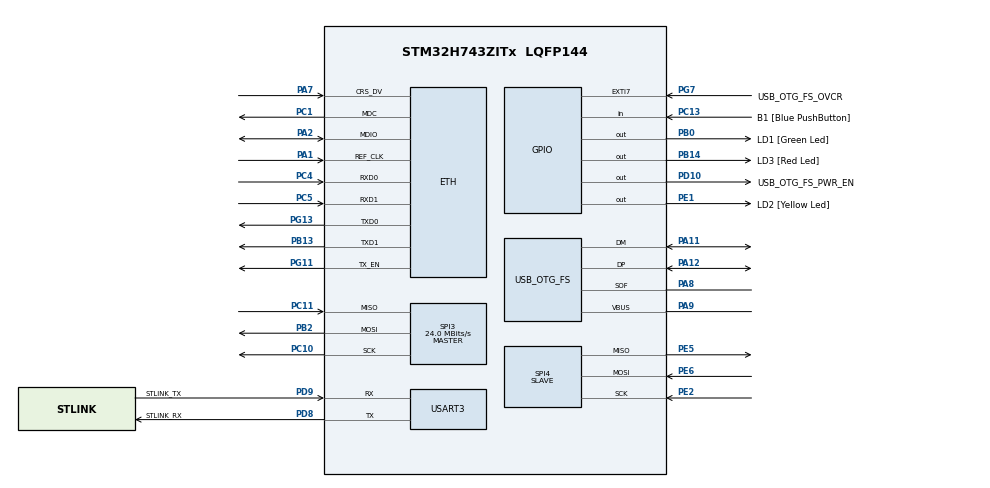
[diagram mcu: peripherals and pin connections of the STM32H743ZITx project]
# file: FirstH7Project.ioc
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Dma.Request0=SPI4_RX
Dma.SPI4_RX.0.Direction=DMA_PERIPH_TO_MEMORY
Dma.SPI4_RX.0.EventEnable=DISABLE
Dma.SPI4_RX.0.FIFOMode=DMA_FIFOMODE_DISABLE
Dma.SPI4_RX.0.Instance=DMA1_Stream0
Dma.SPI4_RX.0.MemDataAlignment=DMA_MDATAALIGN_HALFWORD
Dma.SPI4_RX.0.MemInc=DMA_MINC_ENABLE
Dma.SPI4_RX.0.Mode=DMA_NORMAL
Dma.SPI4_RX.0.PeriphDataAlignment=DMA_PDATAALIGN_HALFWORD
Dma.SPI4_RX.0.PeriphInc=DMA_PINC_DISABLE
Dma.SPI4_RX.0.Polarity=HAL_DMAMUX_REQ_GEN_RISING
Dma.SPI4_RX.0.Priority=DMA_PRIORITY_LOW
Dma.SPI4_RX.0.RequestNumber=1
Dma.SPI4_RX.0.SignalID=NONE
Dma.SPI4_RX.0.SyncEnable=DISABLE
Dma.SPI4_RX.0.SyncPolarity=HAL_DMAMUX_SYNC_NO_EVENT
Dma.SPI4_RX.0.SyncRequestNumber=1
Dma.SPI4_RX.0.SyncSignalID=NONE
ETH.MediaInterface=HAL_ETH_RMII_MODE
Mcu.Family=STM32H7
Mcu.Name=STM32H743ZITx
Mcu.Package=LQFP144
NVIC.DMA1_Stream0_IRQn=true\:0\:0\:false\:false\:true\:false\:true
NVIC.OTG_FS_IRQn=true\:0\:0\:false\:false\:true\:false\:true
NVIC.PriorityGroup=NVIC_PRIORITYGROUP_4
NVIC.SPI4_IRQn=true\:0\:0\:false\:false\:true\:false\:true
PA1.Mode=RMII
PA1.Signal=ETH_REF_CLK
PA11.Mode=Device_Only
PA11.Signal=USB_OTG_FS_DM
PA12.Mode=Device_Only
PA12.Signal=USB_OTG_FS_DP
PA2.Mode=RMII
PA2.Signal=ETH_MDIO
PA7.Mode=RMII
PA7.Signal=ETH_CRS_DV
PA8.Mode=Activate_SOF_FS
PA8.Signal=USB_OTG_FS_SOF
PA9.Mode=Activate_VBUS
PA9.Signal=USB_OTG_FS_VBUS
PB0.GPIO_Label=LD1 [Green Led]
PB0.Signal=GPIO_Output
PB13.Mode=RMII
PB13.Signal=ETH_TXD1
PB14.GPIO_Label=LD3 [Red Led]
PB14.Signal=GPIO_Output
PB2.Mode=Full_Duplex_Master
PB2.Signal=SPI3_MOSI
PC1.Mode=RMII
PC1.Signal=ETH_MDC
PC10.Mode=Full_Duplex_Master
PC10.Signal=SPI3_SCK
PC11.Mode=Full_Duplex_Master
PC11.Signal=SPI3_MISO
PC13.GPIO_Label=B1 [Blue PushButton]
PC13.Signal=GPIO_Input
PC14-OSC32_IN\ (OSC32_IN).Mode=LSE-External-Oscillator
PC14-OSC32_IN\ (OSC32_IN).Signal=RCC_OSC32_IN
PC15-OSC32_OUT\ (OSC32_OUT).Mode=LSE-External-Oscillator
PC15-OSC32_OUT\ (OSC32_OUT).Signal=RCC_OSC32_OUT
PC4.Mode=RMII
PC4.Signal=ETH_RXD0
PC5.Mode=RMII
PC5.Signal=ETH_RXD1
PD10.GPIO_Label=USB_OTG_FS_PWR_EN
PD10.Signal=GPIO_Output
PD8.GPIO_Label=STLINK_RX
PD8.Mode=Asynchronous
PD8.Signal=USART3_TX
PD9.GPIO_Label=STLINK_TX
PD9.Mode=Asynchronous
PD9.Signal=USART3_RX
PE1.GPIO_Label=LD2 [Yellow Led]
PE1.Signal=GPIO_Output
PE2.Mode=Full_Duplex_Slave
PE2.Signal=SPI4_SCK
PE5.Mode=Full_Duplex_Slave
PE5.Signal=SPI4_MISO
PE6.Mode=Full_Duplex_Slave
PE6.Signal=SPI4_MOSI
PG11.Mode=RMII
PG11.Signal=ETH_TX_EN
PG13.Mode=RMII
PG13.Signal=ETH_TXD0
PG7.GPIO_Label=USB_OTG_FS_OVCR
PG7.Signal=GPXTI7
PH0-OSC_IN\ (PH0).Mode=HSE-External-Clock-Source
PH0-OSC_IN\ (PH0).Signal=RCC_OSC_IN
PH1-OSC_OUT\ (PH1).Signal=RCC_OSC_OUT
ProjectManager.HeapSize=0x200
ProjectManager.StackSize=0x400
ProjectManager.TargetToolchain=Makefile
RCC.ADCFreq_Value=16125000
RCC.APB1Freq_Value=64000000
RCC.APB2Freq_Value=64000000
RCC.APB3Freq_Value=64000000
RCC.APB4Freq_Value=64000000
RCC.CortexFreq_Value=64000000
RCC.DIVM1=1
RCC.DIVN1=24
RCC.DIVQ1=4
RCC.HCLKFreq_Value=64000000
RCC.HSE_VALUE=8000000
RCC.PLLFRACN=0
RCC.SYSCLKFreq_VALUE=64000000
RCC.USBFreq_Value=48000000
SPI3.CalculateBaudRate=24.0 MBits/s
SPI3.Direction=SPI_DIRECTION_2LINES
SPI3.Mode=SPI_MODE_MASTER
SPI3.VirtualType=VM_MASTER
SPI4.Direction=SPI_DIRECTION_2LINES
SPI4.Mode=SPI_MODE_SLAVE
SPI4.VirtualType=VM_SLAVE
USART3.VirtualMode-Asynchronous=VM_ASYNC
USB_DEVICE.CLASS_NAME_FS=AUDIO
USB_DEVICE.VirtualMode-AUDIO_FS=Audio
USB_DEVICE.VirtualModeFS=Audio_FS
USB_OTG_FS.VirtualMode=Device_Only
VP_DMA2D_VS_DMA2D.Mode=DMA2D_Activate
VP_USB_DEVICE_VS_USB_DEVICE_AUDIO_FS.Mode=AUDIO_FS
board=NUCLEO-H743ZI2

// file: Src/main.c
/* USER CODE BEGIN Header */
/**
  ******************************************************************************
  * @file           : main.c
  * @brief          : Main program body
  ******************************************************************************
  * @attention
  *
  * <h2><center>&copy; Copyright (c) 2020 STMicroelectronics.
  * All rights reserved.</center></h2>
  *
  * This software component is licensed by ST under BSD 3-Clause license,
  * the "License"; You may not use this file except in compliance with the
  * License. You may obtain a copy of the License at:
  *                        opensource.org/licenses/BSD-3-Clause
  *
  ******************************************************************************
  */
/* USER CODE END Header */
#include "main.h"
#include "dma.h"
#include "dma2d.h"
#include "eth.h"
#include "spi.h"
#include "usart.h"
#include "usb_device.h"
#include "gpio.h"

void SystemClock_Config(void);

int main(void)
{

  /* MCU Configuration--------------------------------------------------------*/

  /* Reset of all peripherals, Initializes the Flash interface and the Systick. */
  HAL_Init();

  /* Configure the system clock */
  SystemClock_Config();

  /* Initialize all configured peripherals */
  MX_GPIO_Init();
  MX_DMA_Init();
  MX_ETH_Init();
  MX_USART3_UART_Init();
  MX_SPI3_Init();
  MX_SPI4_Init();
  MX_USB_DEVICE_Init();
  MX_DMA2D_Init();

  /* Infinite loop */
  /* USER CODE BEGIN WHILE */
    while (1)
    {
        if (HAL_GPIO_ReadPin(B1_GPIO_Port, B1_Pin))
        {
            HAL_GPIO_WritePin(LD3_GPIO_Port, LD3_Pin, GPIO_PIN_SET);
            HAL_GPIO_WritePin(LD2_GPIO_Port, LD2_Pin, GPIO_PIN_SET);
            HAL_GPIO_WritePin(LD1_GPIO_Port, LD1_Pin, GPIO_PIN_SET);
        }
        else
        {
            HAL_GPIO_WritePin(LD3_GPIO_Port, LD3_Pin, GPIO_PIN_RESET);
            HAL_GPIO_WritePin(LD2_GPIO_Port, LD2_Pin, GPIO_PIN_RESET);
            HAL_GPIO_WritePin(LD1_GPIO_Port, LD1_Pin, GPIO_PIN_RESET);
        }
    /* USER CODE END WHILE */

    }
}

void SystemClock_Config(void)
{
  RCC_OscInitTypeDef RCC_OscInitStruct = {0};
  RCC_ClkInitTypeDef RCC_ClkInitStruct = {0};
  RCC_PeriphCLKInitTypeDef PeriphClkInitStruct = {0};

  /** Supply configuration update enable
  */
  HAL_PWREx_ConfigSupply(PWR_LDO_SUPPLY);
  /** Configure the main internal regulator output voltage
  */
  __HAL_PWR_VOLTAGESCALING_CONFIG(PWR_REGULATOR_VOLTAGE_SCALE3);

  while(!__HAL_PWR_GET_FLAG(PWR_FLAG_VOSRDY)) {}
  /** Initializes the RCC Oscillators according to the specified parameters
  * in the RCC_OscInitTypeDef structure.
  */
  RCC_OscInitStruct.OscillatorType = RCC_OSCILLATORTYPE_HSI|RCC_OSCILLATORTYPE_HSE;
  RCC_OscInitStruct.HSEState = RCC_HSE_BYPASS;
  RCC_OscInitStruct.HSIState = RCC_HSI_DIV1;
  RCC_OscInitStruct.HSICalibrationValue = RCC_HSICALIBRATION_DEFAULT;
  RCC_OscInitStruct.PLL.PLLState = RCC_PLL_ON;
  RCC_OscInitStruct.PLL.PLLSource = RCC_PLLSOURCE_HSE;
  RCC_OscInitStruct.PLL.PLLM = 1;
  RCC_OscInitStruct.PLL.PLLN = 24;
  RCC_OscInitStruct.PLL.PLLP = 2;
  RCC_OscInitStruct.PLL.PLLQ = 4;
  RCC_OscInitStruct.PLL.PLLR = 2;
  RCC_OscInitStruct.PLL.PLLRGE = RCC_PLL1VCIRANGE_3;
  RCC_OscInitStruct.PLL.PLLVCOSEL = RCC_PLL1VCOWIDE;
  RCC_OscInitStruct.PLL.PLLFRACN = 0;
  if (HAL_RCC_OscConfig(&RCC_OscInitStruct) != HAL_OK)
  {
    Error_Handler();
  }
  /** Initializes the CPU, AHB and APB buses clocks
  */
  RCC_ClkInitStruct.ClockType = RCC_CLOCKTYPE_HCLK|RCC_CLOCKTYPE_SYSCLK
                              |RCC_CLOCKTYPE_PCLK1|RCC_CLOCKTYPE_PCLK2
                              |RCC_CLOCKTYPE_D3PCLK1|RCC_CLOCKTYPE_D1PCLK1;
  RCC_ClkInitStruct.SYSCLKSource = RCC_SYSCLKSOURCE_HSI;
  RCC_ClkInitStruct.SYSCLKDivider = RCC_SYSCLK_DIV1;
  RCC_ClkInitStruct.AHBCLKDivider = RCC_HCLK_DIV1;
  RCC_ClkInitStruct.APB3CLKDivider = RCC_APB3_DIV1;
  RCC_ClkInitStruct.APB1CLKDivider = RCC_APB1_DIV1;
  RCC_ClkInitStruct.APB2CLKDivider = RCC_APB2_DIV1;
  RCC_ClkInitStruct.APB4CLKDivider = RCC_APB4_DIV1;

  if (HAL_RCC_ClockConfig(&RCC_ClkInitStruct, FLASH_LATENCY_0) != HAL_OK)
  {
    Error_Handler();
  }
  PeriphClkInitStruct.PeriphClockSelection = RCC_PERIPHCLK_USART3|RCC_PERIPHCLK_SPI4
                              |RCC_PERIPHCLK_SPI3|RCC_PERIPHCLK_USB;
  PeriphClkInitStruct.Spi123ClockSelection = RCC_SPI123CLKSOURCE_PLL;
  PeriphClkInitStruct.Spi45ClockSelection = RCC_SPI45CLKSOURCE_D2PCLK1;
  PeriphClkInitStruct.Usart234578ClockSelection = RCC_USART234578CLKSOURCE_D2PCLK1;
  PeriphClkInitStruct.UsbClockSelection = RCC_USBCLKSOURCE_PLL;
  if (HAL_RCCEx_PeriphCLKConfig(&PeriphClkInitStruct) != HAL_OK)
  {
    Error_Handler();
  }
  /** Enable USB Voltage detector
  */
  HAL_PWREx_EnableUSBVoltageDetector();
}

void Error_Handler(void)
{
}

/************************ (C) COPYRIGHT STMicroelectronics *****END OF FILE****/
